# MCXN947_cm33_core0 register map
Vendor: nxp.com; File version: 1.0
CPU: CM33 r2p0, little endian, MPU, FPU, VTOR, 3 interrupt priority bits
Registers are 32-bit, read-write, reset 0x0 unless marked. A register's access mark holds for its fields unless they carry their own. Offsets are from the block's base; [hi:lo] are bit positions; {n}, {i} and the like mark numbered series.

## VREF0 — VREF
Base 0x40111000
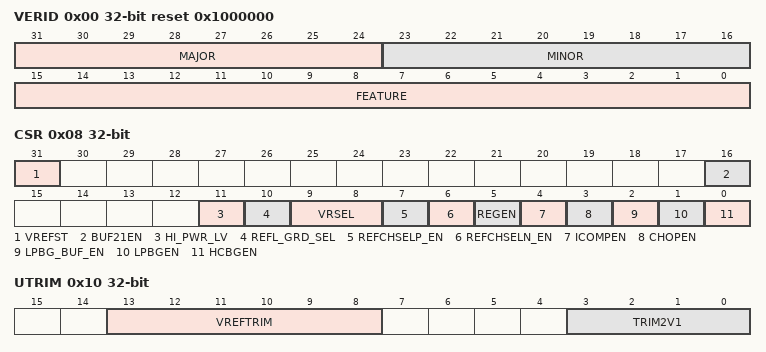
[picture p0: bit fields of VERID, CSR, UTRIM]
0x00 VERID ro reset 0x1000000 — Version ID
  [31:24] MAJOR — Major Version Number
  [23:16] MINOR — Minor Version Number
  [15:0] FEATURE — Feature Specification Number
0x04 PARAM ro — Parameters
0x08 CSR — Control and Status
  [31] VREFST ro — Internal HC Voltage Reference Stable
    0=DIS_NOTSTABLE (Disabled and unstable); 1=STABLE
  [16] BUF21EN — Internal Buffer21 Enable
    0=DIS (Disables); 1=ENA (Enables)
  [11] HI_PWR_LV — High-Power Level
    0=LOW (Low-power); 1=HIGH (High-power)
  [10] REFL_GRD_SEL — Ground Select
    0=VREFL_3V; 1=VSSA
  [9:8] VRSEL — Voltage Reference Selection
    0=BANDGAP (Internal bandgap); 1=ONE_V (Low-power buffered 1v); 2=TWO_PT_ONE_V (Buffer 2.1v output)
  [7] REFCHSELP_EN — Reference Channel Select Positive Enable
    0=DIS (Disables); 1=ENA (Enables)
  [6] REFCHSELN_EN — Reference Channel Select Negative Enable
    0=DIS (Disables); 1=ENA (Enables)
  [5] REGEN — Regulator Enable
    0=DIS (Disables); 1=ENA (Enables)
  [4] ICOMPEN — Current Compensation Enable
    0=DIS (Disables); 1=ENA (Enables)
  [3] CHOPEN — Chop Oscillator Enable
    0=DIS (Disables); 1=ENA (Enables)
  [2] LPBG_BUF_EN — Low-Power Bandgap Buffer Enable
    0=DIS (Disables); 1=ENA (Enables)
  [1] LPBGEN — Low-Power Bandgap Enable
    0=DIS (Disables); 1=ENA (Enables)
  [0] HCBGEN — HC Bandgap Enabled
    0=DIS (Disables); 1=ENA (Enables)
0x10 UTRIM reset not defined — User Trim
  [13:8] VREFTRIM
  [3:0] TRIM2V1 — VREF 2.1V Trim

## SCnSCB
Base 0xE000E000
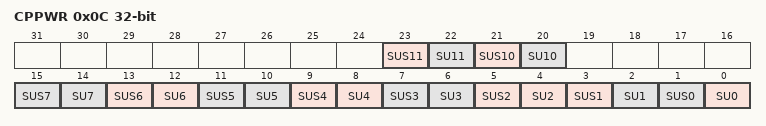
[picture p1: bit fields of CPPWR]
0x0C CPPWR reset not defined — Coprocessor Power Control Register
  [23] SUS11 — State UNKNOWN Secure only 11.
  [22] SU11 — State UNKNOWN 11.
  [21] SUS10 — State UNKNOWN Secure only 10.
    0=SECURE_AND_NON_SECURE (The SU10 field is accessible from both Security states.); 1=SECURE_ONLY (The SU10 field is only accessible from the Secure state.)
  [20] SU10 — State UNKNOWN 10.
    0=UNKNOWN_NOT_PERMITTED (The floating-point state is not permitted to become UNKNOWN.); 1=UNKNOWN_PERMITTED (The floating-point state is permitted to become UNKNOWN)
  [2n+1] SUS{n} (n=2..7) — State UNKNOWN Secure only {n}.
    0=SECURE_AND_NON_SECURE (The SU{n} field is accessible from both Security states.); 1=SECURE_ONLY (The SU{n} field is only accessible from the Secure state.)
  [2n] SU{n} (n=0..7) — State UNKNOWN {n}.
    0=UNKNOWN_NOT_PERMITTED (The coprocessor state is not permitted to become UNKNOWN.); 1=UNKNOWN_PERMITTED (The coprocessor state is permitted to become UNKNOWN.)
  [3] SUS1 — State UNKNOWN Secure only 1.
    0=SECURE_AND_NON_SECURE (The SU7 field is accessible from both Security states.); 1=SECURE_ONLY (The SU7 field is only accessible from the Secure state.)
  [1] SUS0 — State UNKNOWN Secure only 0.
    0=SECURE_AND_NON_SECURE (The SU0 field is accessible from both Security states.); 1=SECURE_ONLY (The SU0 field is only accessible from the Secure state.)

## SysTick0 — M33 Systick module
Base 0xE000E010
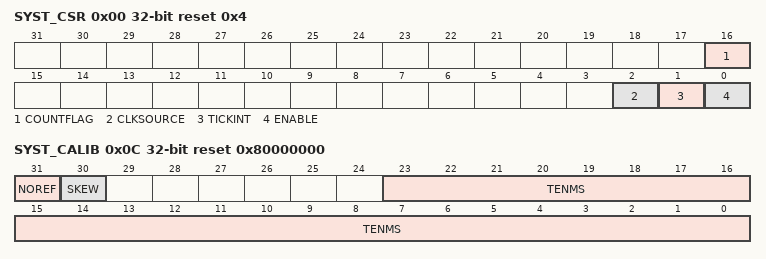
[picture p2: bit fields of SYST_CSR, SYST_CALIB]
0x00 SYST_CSR reset 0x4 — SysTick Control and Status Register
  [16] COUNTFLAG — Returns 1 if timer counted to 0 since the last read of this register.
  [2] CLKSOURCE — Clock source selection.
    0=EXTERNAL_CLOCK; 1=PROCESSOR_CLOCK
  [1] TICKINT — Enable Systick interrupt.
    0=INTERRUPT_DISABLED (counting down to 0 does not assert the SysTick exception request); 1=INTERRUPT_ENABLED (counting down to 0 asserts the SysTick exception request)
  [0] ENABLE — Enable/disable systick counter
    0=COUNTER_DISABLED; 1=COUNTER_ENABLED
0x04 SYST_RVR — SysTick Reload Value Register
  [23:0] RELOAD — Value to load into the SysTick Current Value Register when the counter reaches 0
0x08 SYST_CVR — SysTick Current Value Register
  [23:0] CURRENT — Current value at the time the register is accessed
0x0C SYST_CALIB ro reset 0x80000000 — SysTick Calibration Value Register
  [31] NOREF — Indicates whether the device provides a reference clock to the processor.
    0=CLOCK_PROVIDED (The reference clock is provided); 1=CLOCK_DISABLED (The reference clock is not provided)
  [30] SKEW — Indicates whether the TENMS value is exact:
    0=EXACT_VALUE (10ms calibration value is exact); 1=INEXACT_VALUE (10ms calibration value is inexact, because of the clock frequency)
  [23:0] TENMS — Reload value to use for 10ms timing
